# f2838x_cm_cm_memorydiagerror_regs register map
Vendor: Texas Instruments
Peripheral module from a debugger description file (folder C2000).
Address unit: 16 bits
Registers are 32-bit, read-only, no defined reset value unless marked. A register's access mark holds for its fields unless they carry their own. Offsets are as the file gives them; lines under a group give offsets from that group; [hi:lo] are bit positions; {n}, {i} and the like mark numbered series; 'fields as' and 'values as' point back to an identical list; <NAME> marks a mode.

## CM_MEMORYDIAGERROR_REGS — CM MEMORYDIAGERROR Registers
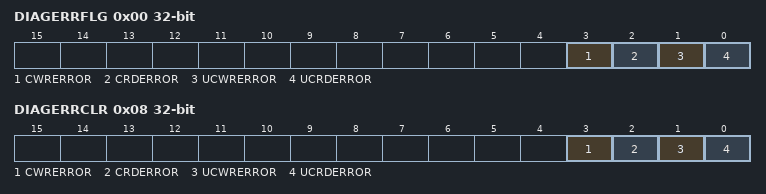
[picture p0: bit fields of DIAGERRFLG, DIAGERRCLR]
0x00 DIAGERRFLG — Error Flag Register
  [3] CWRERROR — Diagnostics Correctable Write Error Flag
  [2] CRDERROR — Diagnostics Correctable Read Error Flag
  [1] UCWRERROR — Diagnostics Uncorrectable Write Error Flag
  [0] UCRDERROR — Diagnostics Uncorrectable Read Error Flag
0x08 DIAGERRCLR rw — Error Flag Clear Register
  [3] CWRERROR — Clear diagnostics correctable Write Error Flag
  [2] CRDERROR — Clear diagnostics correctable Read Error Flag
  [1] UCWRERROR — Clear diagnostics uncorrectable Write Error Flag
  [0] UCRDERROR — Clear diagnostics uncorrectable Read Error Flag
0x0C DIAGERRADDR — Read Error Address
  [31:0] EADDR — Diagnostics Error address register
